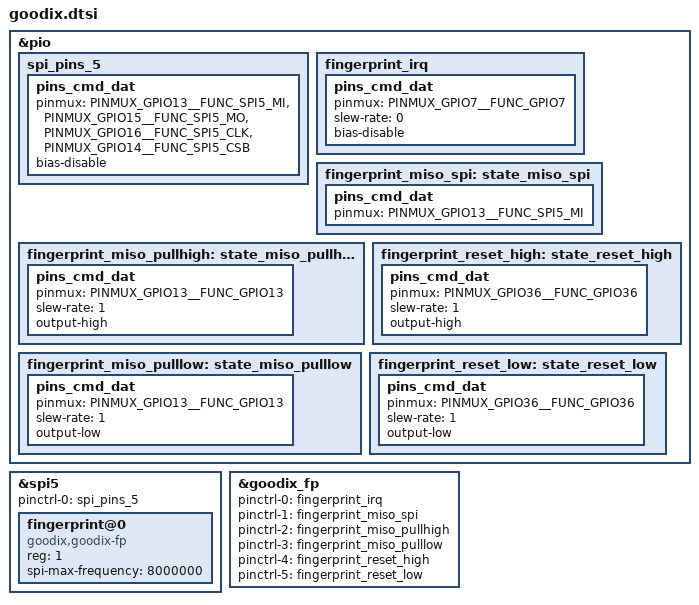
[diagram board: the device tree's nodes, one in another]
/* silead fingerprint ctrl start */
&pio{
	spi_pins_5:spi_pins_5{
		pins_cmd_dat{
			pinmux = <PINMUX_GPIO13__FUNC_SPI5_MI>,
				<PINMUX_GPIO15__FUNC_SPI5_MO>,
				<PINMUX_GPIO16__FUNC_SPI5_CLK>,
				<PINMUX_GPIO14__FUNC_SPI5_CSB>;
				bias-disable;
		};
	};
};
&spi5 {
	#address-cells = <1>;
	#size-cells = <0>;
	pinctrl-names = "default";
	pinctrl-0 = <&spi_pins_5>;
	status = "okay";
	
	fingerprint@0 {
		compatible = "goodix,goodix-fp";
		reg = <1>;
		spi-max-frequency = <8000000>;
		status = "okay";
	};
};
&pio {

	fingerprint_irq: fingerprint_irq {
		pins_cmd_dat {
			pinmux = <PINMUX_GPIO7__FUNC_GPIO7>;
			slew-rate = <0>;
			bias-disable;
		};
	};
	fingerprint_miso_spi: state_miso_spi {
		pins_cmd_dat {
			pinmux = <PINMUX_GPIO13__FUNC_SPI5_MI>;
		};
	};
	fingerprint_miso_pullhigh: state_miso_pullhigh {
		pins_cmd_dat {
			pinmux = <PINMUX_GPIO13__FUNC_GPIO13>;
			slew-rate = <1>;
			output-high;
		};
	};
	fingerprint_miso_pulllow: state_miso_pulllow {
		pins_cmd_dat {
			pinmux = <PINMUX_GPIO13__FUNC_GPIO13>;
			slew-rate = <1>;
			output-low;
		};
	};
	fingerprint_reset_high: state_reset_high {
		pins_cmd_dat {
			pinmux = <PINMUX_GPIO36__FUNC_GPIO36>;
			slew-rate = <1>;
			output-high;
		};
	};
	fingerprint_reset_low: state_reset_low {
		pins_cmd_dat {
			pinmux = <PINMUX_GPIO36__FUNC_GPIO36>;
			slew-rate = <1>;
			output-low;
		};
	};
};
&goodix_fp {
	pinctrl-names = "fingerprint_irq", "miso_spi", "miso_pullhigh", "miso_pulllow", "reset_high",
	"reset_low";
	pinctrl-0 = <&fingerprint_irq>;
	pinctrl-1 = <&fingerprint_miso_spi>;
	pinctrl-2 = <&fingerprint_miso_pullhigh>;
	pinctrl-3 = <&fingerprint_miso_pulllow>;
	pinctrl-4 = <&fingerprint_reset_high>;
	pinctrl-5 = <&fingerprint_reset_low>;
	status = "okay";
};





		

/* silead fingerprint ctrl end */
